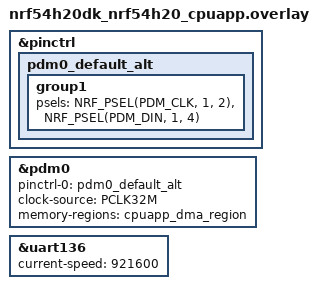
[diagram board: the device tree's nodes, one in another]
/*
 * Copyright (c) 2025 Nordic Semiconductor ASA
 *
 * SPDX-License-Identifier: LicenseRef-Nordic-5-Clause
 */

&pinctrl {
	pdm0_default_alt: pdm0_default_alt {
		group1 {
			psels = <NRF_PSEL(PDM_CLK, 1, 2)>,
				<NRF_PSEL(PDM_DIN, 1, 4)>;
		};
	};
};

dmic_dev: &pdm0 {
	status = "okay";
	pinctrl-0 = <&pdm0_default_alt>;
	pinctrl-names = "default";
	clock-source = "PCLK32M";
	memory-regions = <&cpuapp_dma_region>;
};

&uart136 {
	current-speed = <921600>;
};
